# ESM_ESM_04100000h register map
Vendor: Texas Instruments
Peripheral module from a debugger description file (folder AM275x).
Registers are 32-bit, read-only, reset 0x0 unless marked. A register's access mark holds for its fields unless they carry their own. Offsets are as the file gives them; lines under a group give offsets from that group; [hi:lo] are bit positions; {n}, {i} and the like mark numbered series; 'fields as' and 'values as' point back to an identical list; <NAME> marks a mode.

## esm
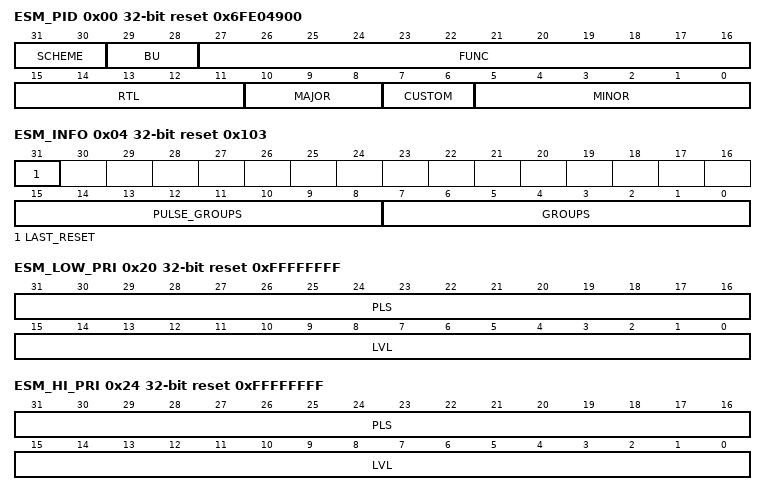
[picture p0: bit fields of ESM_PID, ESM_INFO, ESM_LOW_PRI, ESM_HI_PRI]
0x00 ESM_PID reset 0x6FE04900 — The Revision Register contains the major and minor revisions for the module.
  [31:30] SCHEME — PID register scheme Reset Source: por_rst_n
  [29:28] BU — Business Unit: 10 = Processors Reset Source: por_rst_n
  [27:16] FUNC — Module ID Reset Source: por_rst_n
  [15:11] RTL — RTL revision. Will vary depending on release. Reset Source: por_rst_n
  [10:8] MAJOR — Major revision Reset Source: por_rst_n
  [7:6] CUSTOM — Custom Reset Source: por_rst_n
  [5:0] MINOR — Minor revision Reset Source: por_rst_n
0x04 ESM_INFO reset 0x103 — The Info Register gives the configuration Inforrmation of this ESM.
  [31] LAST_RESET — Indicates the Source of the last Reset Reset Source: por_rst_n
  [15:8] PULSE_GROUPS — Number of Pulse Error Groups Reset Source: por_rst_n
  [7:0] GROUPS — Total number of Error Groups Reset Source: por_rst_n
0x08 ESM_EN rw — The Global Enable Register has the initiator interrupt mask
  [3:0] KEY — Global Enable Reset Source: por_rst_n
0x0C ESM_SFT_RST wo — The Global Soft Reset Register controls the global clear for raw status and enables
  [3:0] KEY — Global Soft Reset Reset Source: por_rst_n
0x10 ESM_ERR_RAW access not given — Raw Status/Set Register for Configuration Errors
  [2:0] STS — This is the raw status for config errors Reset Source: por_rst_n (access R/W1TS)
0x14 ESM_ERR_STS access not given — Config Error Enable and Clear Register
  [2:0] MSK — This is the masked status/clear for config errors Reset Source: por_rst_n (access R/W1TC)
0x18 ESM_ERR_EN_SET access not given — Config Error Enable Set Register
  [2:0] MSK — This is the mask enable set for config errors Reset Source: por_rst_n (access R/W1TS)
0x1C ESM_ERR_EN_CLR access not given — Config Error Interrupt Enabled Clear register
  [2:0] MSK — This is the mask enable clear for config errors Reset Source: por_rst_n (access R/W1TC)
0x20 ESM_LOW_PRI reset 0xFFFFFFFF — Shows which is the highest priority outstanding low priority interrupt
  [31:16] PLS — This is the highest priority outstanding low priority pulse interrupt Reset Source: por_rst_n
  [15:0] LVL — This is the highest priority outstanding low priority level interrupt Reset Source: por_rst_n
0x24 ESM_HI_PRI reset 0xFFFFFFFF — Shows which is the highest priority outstanding high priority interrupt
  [31:16] PLS — This is the highest priority outstanding high priority pulse interrupt Reset Source: por_rst_n
  [15:0] LVL — This is the highest priority outstanding high priority level interrupt Reset Source: por_rst_n
0x28 ESM_LOW — Shows which groups have oustanding low priority interrupts
  [31:0] STS — This is the raw status for config errors Reset Source: por_rst_n
0x2C ESM_HI — Shows which groups have oustanding high priority interrupts
  fields as ESM_LOW
0x30 ESM_EOI wo — End of Interrupt Register
  [10:0] KEY — This is the interrupt being serviced Reset Source: por_rst_n
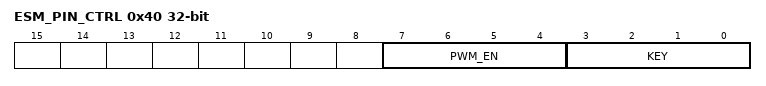
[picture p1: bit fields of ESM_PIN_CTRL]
0x40 ESM_PIN_CTRL rw — This register controls the error_pin_n output
  [7:4] PWM_EN — PWM enable Reset Source: por_rst_n
  [3:0] KEY — Pin Control Key Reset Source: por_rst_n
0x44 ESM_PIN_STS — This register reflects the status of the error_pin_n output
  [0] VAL — Value of the error_pin_n Reset Source: por_rst_n
0x48 ESM_PIN_CNTR — This register shows the current value of the error pin counter
  [23:0] COUNT — Current Counter Value Reset Source: por_rst_n
0x4C ESM_PIN_CNTR_PRE rw — This register contains the value that is loaded in to the Error Counter
  [23:0] COUNT — Counter Pre-Load Value Reset Source: por_rst_n
0x50 ESM_PWMH_PIN_CNTR — This register shows the current value of the error pin PWM high counter
  [23:0] COUNT — Current Counter Value Reset Source: por_rst_n
0x54 ESM_PWMH_PIN_CNTR_PRE rw — This register contains the value that is loaded in to the Error PWM High Counter
  [23:0] COUNT — Counter Pre-Load Value Reset Source: por_rst_n
0x58 ESM_PWML_PIN_CNTR — This register shows the current value of the error pin PWM low counter
  [23:0] COUNT — Current Counter Value Reset Source: por_rst_n
0x5C ESM_PWML_PIN_CNTR_PRE rw — This register contains the value that is loaded in to the Error PWM Low Counter
  [23:0] COUNT — Counter Pre-Load Value Reset Source: por_rst_n
0x400 ESM_ERR_GRP_RAW_j access not given — Raw Status/Set Register for Group A Errors
  [31:0] STS — This is the raw status/set for errors Group A Reset Source: por_rst_n (access R/W1TS)
0x404 ESM_ERR_GRP_STS_j access not given — Error Enable and Clear Register
  [31:0] MSK — This is the masked status/clear for errors in Group A Reset Source: por_rst_n (access R/W1TC)
0x408 ESM_ERR_GRP_INTR_EN_SET_j access not given — Level Error Enable Set Register
  [31:0] MSK — This is the mask enable set for errors in Group A Reset Source: por_rst_n (access R/W1TS)
0x40C ESM_ERR_GRP_INTR_EN_CLR_j access not given — Level Error Interrupt Enabled Clear register
  [31:0] MSK — This is the mask enable clear for errors in Group A Reset Source: por_rst_n (access R/W1TC)
0x410 ESM_ERR_GRP_INT_PRIO_j rw — Level Error Interrupt Enabled Clear register
  [31:0] MSK — This is interrupt priority for errors in Group A Reset Source: por_rst_n
0x414 ESM_ERR_GRP_PIN_EN_SET_j access not given — Level Error Interrupt Enabled Clear register
  [31:0] MSK — This is the error pin influence enable set for errors in Group A Reset Source: por_rst_n (access R/W1TS)
0x418 ESM_ERR_GRP_PIN_EN_CLR_j access not given — Level Error Interrupt Enabled Clear register
  [31:0] MSK — This is the error pin influence enable clear for errors in Group A Reset Source: por_rst_n (access R/W1TC)
